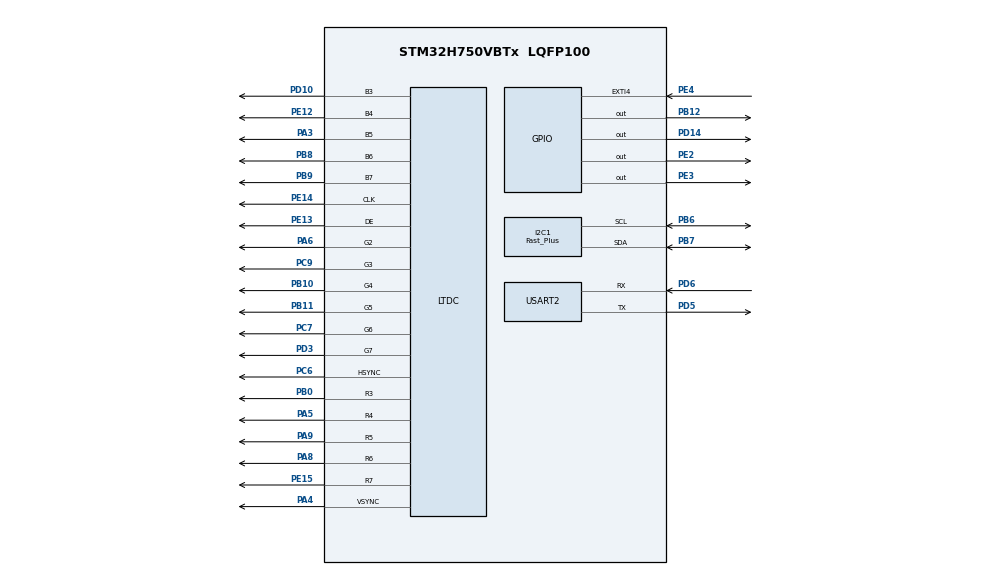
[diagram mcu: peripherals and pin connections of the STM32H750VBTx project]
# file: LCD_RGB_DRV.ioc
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CORTEX_M7.default_mode_Activation=1
DMA2D.ColorMode=DMA2D_OUTPUT_RGB565
I2C1.CustomTiming=Disabled
I2C1.I2C_Speed_Mode=I2C_Fast_Plus
I2C1.Timing=0x0050174F
LTDC.ActiveH=272
LTDC.ActiveW=480
LTDC.Alpha_L0=255
LTDC.BlendingFactor1_L0=LTDC_BLENDING_FACTOR1_PAxCA
LTDC.BlendingFactor2_L0=LTDC_BLENDING_FACTOR2_PAxCA
LTDC.Green=255
LTDC.HBP=43
LTDC.HFP=75
LTDC.HSync=75
LTDC.ImageHeight_L0=272
LTDC.ImageWidth_L0=480
LTDC.Layers=0
LTDC.PixelFormat_L0=LTDC_PIXEL_FORMAT_RGB565
LTDC.VBP=12
LTDC.VFP=37
LTDC.VSync=37
LTDC.WindowX1_L0=480
LTDC.WindowY1_L0=272
Mcu.Family=STM32H7
Mcu.Name=STM32H750VBTx
Mcu.Package=LQFP100
NVIC.EXTI4_IRQn=true\:1\:0\:true\:false\:true\:true\:true\:true
NVIC.LTDC_IRQn=true\:0\:0\:false\:false\:true\:true\:true\:true
NVIC.PriorityGroup=NVIC_PRIORITYGROUP_4
NVIC.TIM3_IRQn=true\:0\:0\:false\:false\:true\:true\:true\:true
PA13\ (JTMS/SWDIO).Mode=Serial_Wire
PA13\ (JTMS/SWDIO).Signal=DEBUG_JTMS-SWDIO
PA14\ (JTCK/SWCLK).Mode=Serial_Wire
PA14\ (JTCK/SWCLK).Signal=DEBUG_JTCK-SWCLK
PA3.GPIO_Speed=GPIO_SPEED_FREQ_VERY_HIGH
PA3.Mode=RGB565
PA3.Signal=LTDC_B5
PA4.GPIO_Speed=GPIO_SPEED_FREQ_VERY_HIGH
PA4.Mode=RGB565
PA4.Signal=LTDC_VSYNC
PA5.GPIO_Speed=GPIO_SPEED_FREQ_VERY_HIGH
PA5.Mode=RGB565
PA5.Signal=LTDC_R4
PA6.GPIO_Speed=GPIO_SPEED_FREQ_VERY_HIGH
PA6.Mode=RGB565
PA6.Signal=LTDC_G2
PA8.GPIO_Speed=GPIO_SPEED_FREQ_VERY_HIGH
PA8.Mode=RGB565
PA8.Signal=LTDC_R6
PA9.GPIO_Speed=GPIO_SPEED_FREQ_VERY_HIGH
PA9.Mode=RGB565
PA9.Signal=LTDC_R5
PB0.GPIO_Speed=GPIO_SPEED_FREQ_VERY_HIGH
PB0.Mode=RGB565
PB0.Signal=LTDC_R3
PB10.GPIO_Speed=GPIO_SPEED_FREQ_VERY_HIGH
PB10.Mode=RGB565
PB10.Signal=LTDC_G4
PB11.GPIO_Speed=GPIO_SPEED_FREQ_VERY_HIGH
PB11.Mode=RGB565
PB11.Signal=LTDC_G5
PB12.GPIO_Speed=GPIO_SPEED_FREQ_VERY_HIGH
PB12.PinState=GPIO_PIN_SET
PB12.Signal=GPIO_Output
PB6.GPIO_Speed=GPIO_SPEED_FREQ_VERY_HIGH
PB6.Mode=I2C
PB6.Signal=I2C1_SCL
PB7.GPIO_Speed=GPIO_SPEED_FREQ_VERY_HIGH
PB7.Mode=I2C
PB7.Signal=I2C1_SDA
PB8.GPIO_Speed=GPIO_SPEED_FREQ_VERY_HIGH
PB8.Mode=RGB565
PB8.Signal=LTDC_B6
PB9.GPIO_Speed=GPIO_SPEED_FREQ_VERY_HIGH
PB9.Mode=RGB565
PB9.Signal=LTDC_B7
PC6.GPIO_Speed=GPIO_SPEED_FREQ_VERY_HIGH
PC6.Mode=RGB565
PC6.Signal=LTDC_HSYNC
PC7.GPIO_Speed=GPIO_SPEED_FREQ_VERY_HIGH
PC7.Mode=RGB565
PC7.Signal=LTDC_G6
PC9.GPIO_Speed=GPIO_SPEED_FREQ_VERY_HIGH
PC9.Mode=RGB565
PC9.Signal=LTDC_G3
PD10.GPIO_Speed=GPIO_SPEED_FREQ_VERY_HIGH
PD10.Mode=RGB565
PD10.Signal=LTDC_B3
PD14.GPIO_Speed=GPIO_SPEED_FREQ_VERY_HIGH
PD14.PinState=GPIO_PIN_SET
PD14.Signal=GPIO_Output
PD3.GPIO_Speed=GPIO_SPEED_FREQ_VERY_HIGH
PD3.Mode=RGB565
PD3.Signal=LTDC_G7
PD5.GPIO_Speed=GPIO_SPEED_FREQ_VERY_HIGH
PD5.Mode=Asynchronous
PD5.Signal=USART2_TX
PD6.GPIO_Speed=GPIO_SPEED_FREQ_VERY_HIGH
PD6.Mode=Asynchronous
PD6.Signal=USART2_RX
PE12.GPIO_Speed=GPIO_SPEED_FREQ_VERY_HIGH
PE12.Mode=RGB565
PE12.Signal=LTDC_B4
PE13.GPIO_Speed=GPIO_SPEED_FREQ_VERY_HIGH
PE13.Mode=RGB565
PE13.Signal=LTDC_DE
PE14.GPIO_Speed=GPIO_SPEED_FREQ_VERY_HIGH
PE14.Mode=RGB565
PE14.Signal=LTDC_CLK
PE15.GPIO_Speed=GPIO_SPEED_FREQ_VERY_HIGH
PE15.Mode=RGB565
PE15.Signal=LTDC_R7
PE2.GPIO_Speed=GPIO_SPEED_FREQ_VERY_HIGH
PE2.Signal=GPIO_Output
PE3.GPIO_Speed=GPIO_SPEED_FREQ_VERY_HIGH
PE3.PinState=GPIO_PIN_RESET
PE3.Signal=GPIO_Output
PE4.Signal=GPXTI4
PH0-OSC_IN\ (PH0).Mode=HSE-External-Oscillator
PH0-OSC_IN\ (PH0).Signal=RCC_OSC_IN
PH1-OSC_OUT\ (PH1).Mode=HSE-External-Oscillator
PH1-OSC_OUT\ (PH1).Signal=RCC_OSC_OUT
ProjectManager.HeapSize=0x200
ProjectManager.StackSize=0x1000
ProjectManager.TargetToolchain=MDK-ARM V5.32
RCC.ADCFreq_Value=50390625
RCC.APB1Freq_Value=120000000
RCC.APB2Freq_Value=120000000
RCC.APB3Freq_Value=120000000
RCC.APB4Freq_Value=120000000
RCC.CortexFreq_Value=480000000
RCC.D1PPRE=RCC_APB3_DIV2
RCC.D2PPRE1=RCC_APB1_DIV2
RCC.D2PPRE2=RCC_APB2_DIV2
RCC.D3PPRE=RCC_APB4_DIV2
RCC.DIVM1=5
RCC.DIVM3=5
RCC.DIVN1=192
RCC.DIVN3=192
RCC.DIVQ1=6
RCC.DIVR1=8
RCC.DIVR3=32
RCC.HCLKFreq_Value=240000000
RCC.HPRE=RCC_HCLK_DIV2
RCC.PLLSourceVirtual=RCC_PLLSOURCE_HSE
RCC.SYSCLKFreq_VALUE=480000000
RCC.SYSCLKSource=RCC_SYSCLKSOURCE_PLLCLK
RCC.USBFreq_Value=160000000
TIM3.AutoReloadPreload=TIM_AUTORELOAD_PRELOAD_ENABLE
TIM3.Period=999
TIM3.Prescaler=239
USART2.VirtualMode-Asynchronous=VM_ASYNC
VP_DMA2D_VS_DMA2D.Mode=DMA2D_Activate
VP_TIM3_VS_ClockSourceINT.Mode=Internal
board=custom

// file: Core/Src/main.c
/* USER CODE BEGIN Header */
/**
  ******************************************************************************
  * @file           : main.c
  * @brief          : Main program body
  ******************************************************************************
  * @attention
  *
  * Copyright (c) 2022 STMicroelectronics.
  * All rights reserved.
  *
  * This software is licensed under terms that can be found in the LICENSE file
  * in the root directory of this software component.
  * If no LICENSE file comes with this software, it is provided AS-IS.
  *
  ******************************************************************************
  */
/* USER CODE END Header */
#include "main.h"
#include "dma2d.h"
#include "i2c.h"
#include "ltdc.h"
#include "tim.h"
#include "usart.h"
#include "gpio.h"

/* USER CODE BEGIN Includes */

#include "bsp.h"//板级支持包
#include "app.h"//lvgl头文件包含在内

/* USER CODE END Includes */

void SystemClock_Config(void);
static void MPU_Config(void);

int main(void)
{

  /* MPU Configuration--------------------------------------------------------*/
  MPU_Config();

  /* MCU Configuration--------------------------------------------------------*/

  /* Reset of all peripherals, Initializes the Flash interface and the Systick. */
  HAL_Init();

  /* Configure the system clock */
  SystemClock_Config();

  /* Initialize all configured peripherals */
  MX_GPIO_Init();
  MX_LTDC_Init();
  MX_I2C1_Init();
  MX_USART2_UART_Init();
  MX_DMA2D_Init();
  MX_TIM3_Init();
  /* USER CODE BEGIN 2 */
  app_lvgl_init();
  app_lvgl_disp();

  // lv_demo_benchmark();
  // lv_demo_music();
  // lv_demo_widgets();

  /* USER CODE END 2 */

  /* Infinite loop */
  /* USER CODE BEGIN WHILE */
  HAL_TIM_Base_Start_IT(&htim3);
  while (1)
  {
    /* USER CODE END WHILE */

    /* USER CODE BEGIN 3 */
	  lv_task_handler();
  }
  /* USER CODE END 3 */
}

void SystemClock_Config(void)
{
  RCC_OscInitTypeDef RCC_OscInitStruct = {0};
  RCC_ClkInitTypeDef RCC_ClkInitStruct = {0};

  /** Supply configuration update enable
  */
  HAL_PWREx_ConfigSupply(PWR_LDO_SUPPLY);

  /** Configure the main internal regulator output voltage
  */
  __HAL_PWR_VOLTAGESCALING_CONFIG(PWR_REGULATOR_VOLTAGE_SCALE0);

  while(!__HAL_PWR_GET_FLAG(PWR_FLAG_VOSRDY)) {}

  /** Macro to configure the PLL clock source
  */
  __HAL_RCC_PLL_PLLSOURCE_CONFIG(RCC_PLLSOURCE_HSE);

  /** Initializes the RCC Oscillators according to the specified parameters
  * in the RCC_OscInitTypeDef structure.
  */
  RCC_OscInitStruct.OscillatorType = RCC_OSCILLATORTYPE_HSE;
  RCC_OscInitStruct.HSEState = RCC_HSE_ON;
  RCC_OscInitStruct.PLL.PLLState = RCC_PLL_ON;
  RCC_OscInitStruct.PLL.PLLSource = RCC_PLLSOURCE_HSE;
  RCC_OscInitStruct.PLL.PLLM = 5;
  RCC_OscInitStruct.PLL.PLLN = 192;
  RCC_OscInitStruct.PLL.PLLP = 2;
  RCC_OscInitStruct.PLL.PLLQ = 6;
  RCC_OscInitStruct.PLL.PLLR = 8;
  RCC_OscInitStruct.PLL.PLLRGE = RCC_PLL1VCIRANGE_2;
  RCC_OscInitStruct.PLL.PLLVCOSEL = RCC_PLL1VCOWIDE;
  RCC_OscInitStruct.PLL.PLLFRACN = 0;
  if (HAL_RCC_OscConfig(&RCC_OscInitStruct) != HAL_OK)
  {
    Error_Handler();
  }

  /** Initializes the CPU, AHB and APB buses clocks
  */
  RCC_ClkInitStruct.ClockType = RCC_CLOCKTYPE_HCLK|RCC_CLOCKTYPE_SYSCLK
                              |RCC_CLOCKTYPE_PCLK1|RCC_CLOCKTYPE_PCLK2
                              |RCC_CLOCKTYPE_D3PCLK1|RCC_CLOCKTYPE_D1PCLK1;
  RCC_ClkInitStruct.SYSCLKSource = RCC_SYSCLKSOURCE_PLLCLK;
  RCC_ClkInitStruct.SYSCLKDivider = RCC_SYSCLK_DIV1;
  RCC_ClkInitStruct.AHBCLKDivider = RCC_HCLK_DIV2;
  RCC_ClkInitStruct.APB3CLKDivider = RCC_APB3_DIV2;
  RCC_ClkInitStruct.APB1CLKDivider = RCC_APB1_DIV2;
  RCC_ClkInitStruct.APB2CLKDivider = RCC_APB2_DIV2;
  RCC_ClkInitStruct.APB4CLKDivider = RCC_APB4_DIV2;

  if (HAL_RCC_ClockConfig(&RCC_ClkInitStruct, FLASH_LATENCY_4) != HAL_OK)
  {
    Error_Handler();
  }
}

/* USER CODE BEGIN 4 */

void HAL_TIM_PeriodElapsedCallback(TIM_HandleTypeDef *htim)
{
	UNUSED(htim);
	lv_tick_inc(1);
}

/* USER CODE END 4 */

/* MPU Configuration */

void MPU_Config(void)
{
  MPU_Region_InitTypeDef MPU_InitStruct = {0};

  /* Disables the MPU */
  HAL_MPU_Disable();

  /** Initializes and configures the Region and the memory to be protected
  */
  MPU_InitStruct.Enable = MPU_REGION_ENABLE;
  MPU_InitStruct.Number = MPU_REGION_NUMBER0;
  MPU_InitStruct.BaseAddress = 0x0;
  MPU_InitStruct.Size = MPU_REGION_SIZE_4GB;
  MPU_InitStruct.SubRegionDisable = 0x87;
  MPU_InitStruct.TypeExtField = MPU_TEX_LEVEL0;
  MPU_InitStruct.AccessPermission = MPU_REGION_NO_ACCESS;
  MPU_InitStruct.DisableExec = MPU_INSTRUCTION_ACCESS_DISABLE;
  MPU_InitStruct.IsShareable = MPU_ACCESS_SHAREABLE;
  MPU_InitStruct.IsCacheable = MPU_ACCESS_NOT_CACHEABLE;
  MPU_InitStruct.IsBufferable = MPU_ACCESS_NOT_BUFFERABLE;

  HAL_MPU_ConfigRegion(&MPU_InitStruct);
  /* Enables the MPU */
  HAL_MPU_Enable(MPU_PRIVILEGED_DEFAULT);

}

void Error_Handler(void)
{
  __disable_irq();
  while (1)
  {
  }
}
